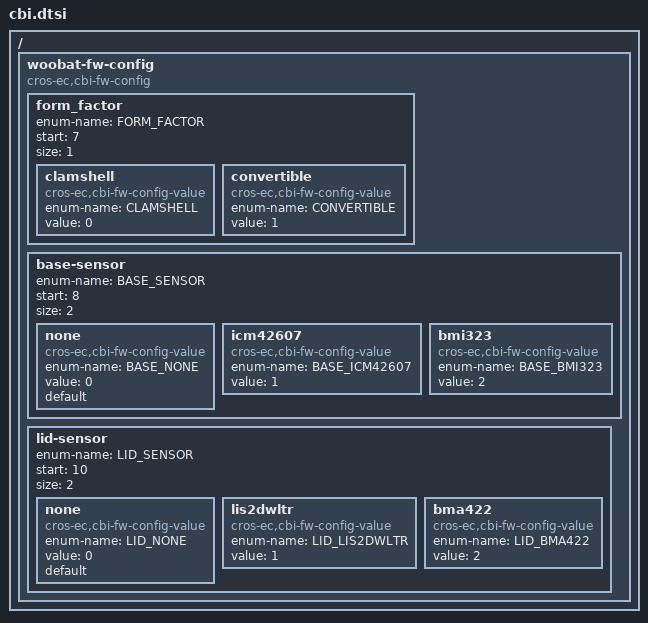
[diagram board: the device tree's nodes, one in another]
/* Copyright 2024 The ChromiumOS Authors
 * Use of this source code is governed by a BSD-style license that can be
 * found in the LICENSE file.
 */

/ {
	/* woobat-specific fw_config fields. */
	woobat-fw-config {
		compatible = "cros-ec,cbi-fw-config";
		/*
		 * FW_CONFIG field to describe mainboard orientation in chassis.
		 */
		form_factor {
			enum-name = "FORM_FACTOR";
			start = <7>;
			size = <1>;

			clamshell {
				compatible = "cros-ec,cbi-fw-config-value";
				enum-name = "CLAMSHELL";
				value = <0>;
			};
			convertible {
				compatible = "cros-ec,cbi-fw-config-value";
				enum-name = "CONVERTIBLE";
				value = <1>;
			};
		};
		base-sensor {
			enum-name = "BASE_SENSOR";
			start = <8>;
			size = <2>;

			none {
				compatible = "cros-ec,cbi-fw-config-value";
				enum-name = "BASE_NONE";
				value = <0>;
				default;
			};
			icm42607 {
				compatible = "cros-ec,cbi-fw-config-value";
				enum-name = "BASE_ICM42607";
				value = <1>;
			};
			bmi323 {
				compatible = "cros-ec,cbi-fw-config-value";
				enum-name = "BASE_BMI323";
				value = <2>;
			};
		};
		lid-sensor {
			enum-name = "LID_SENSOR";
			start = <10>;
			size = <2>;

			none {
				compatible = "cros-ec,cbi-fw-config-value";
				enum-name = "LID_NONE";
				value = <0>;
				default;
			};
			lis2dwltr {
				compatible = "cros-ec,cbi-fw-config-value";
				enum-name = "LID_LIS2DWLTR";
				value = <1>;
			};
			bma422 {
				compatible = "cros-ec,cbi-fw-config-value";
				enum-name = "LID_BMA422";
				value = <2>;
			};
		};
	};
};
